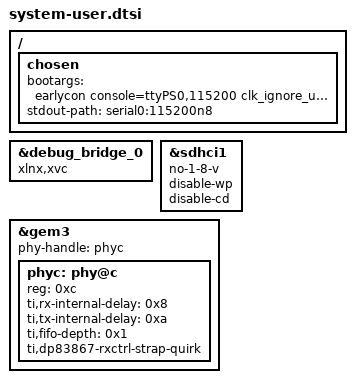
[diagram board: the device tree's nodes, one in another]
/include/ "system-conf.dtsi"
/ {
  chosen {
          // bootargs = "earlycon console=ttyPS0,115200 clk_ignore_unused root=/dev/mmcblk0p2 rw cpuidle.off=1"; // mmc ext4
           bootargs = "earlycon console=ttyPS0,115200 clk_ignore_unused root=/dev/ram0 rw cpuidle.off=1"; // initrd
          // bootargs = "earlycon console=ttyPS0,115200 clk_ignore_unused cpuidle.off=1"; // initramfs
          stdout-path = "serial0:115200n8";
  };
};

&debug_bridge_0 {
        compatible = "xlnx,xvc";
};


&sdhci1 {
    no-1-8-v; // 1.8V to 3.3V level shifter (i.e. using LVCMOS18, but sd connector is driven by 3.3V)
    disable-wp;
    disable-cd;
};

&gem3 {
    phy-handle = <&phyc>;
    phyc: phy@c {
        reg = <0xc>;
        ti,rx-internal-delay = <0x8>;
        ti,tx-internal-delay = <0xa>;
        ti,fifo-depth = <0x1>;
        ti,dp83867-rxctrl-strap-quirk;
    };
};
